VERSION "sdv-demo-powertrain-v2.0"

NS_ :

BS_:

BU_: VCU BMS Gateway

// ─── GLOBAL — ECU → Gateway, strictly VSS-aligned ───────────────────
// Every signal maps 1:1 to a VSS leaf; the Powertrain Gateway bridges
// CAN → KUKSA (read-only, sensor direction). Signal names follow the VSS
// leaf name. Cross-domain consumers (AAOS VHAL, AGL cluster) read these
// from KUKSA only — never off this bus.
//
// EV framing (no combustion engine). Producers (demo):
//   VCU = vcu.lua (speed / electric-motor rpm / odometer / gear / drive mode)
//   BMS = bms.lua (traction battery / range)

BO_ 256 PWT_VehicleSpeed: 4 VCU
 SG_ Speed_kph : 0|16@1+ (0.1,0) [0|300] "km/h" Gateway

BO_ 272 PWT_MotorSpeed: 2 VCU
 SG_ Speed_rpm : 0|16@1+ (0.25,0) [0|16000] "rpm" Gateway

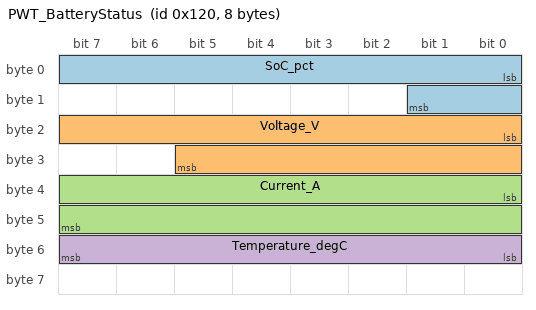
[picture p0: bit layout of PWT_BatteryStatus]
BO_ 288 PWT_BatteryStatus: 8 BMS
 SG_ SoC_pct : 0|10@1+ (0.1,0) [0|100] "%" Gateway
 SG_ Voltage_V : 16|14@1+ (0.1,0) [0|1000] "V" Gateway
 SG_ Current_A : 32|16@1- (0.1,0) [-3276.8|3276.7] "A" Gateway
 SG_ Temperature_degC : 48|8@1- (1,-40) [-40|150] "degC" Gateway

BO_ 304 PWT_Odometer: 4 VCU
 SG_ TraveledDistance_m : 0|32@1+ (1,0) [0|4294967295] "m" Gateway

BO_ 320 PWT_Range: 4 BMS
 SG_ Range_m : 0|32@1+ (1,0) [0|4294967295] "m" Gateway

BO_ 336 PWT_DrivetrainStatus: 2 VCU
 SG_ SelectedGear : 0|8@1- (1,0) [-128|127] "" Gateway
 SG_ PerformanceMode : 8|3@1+ (1,0) [0|4] "" Gateway

// SelectedGear uses the VSS-native int8 PRNDL encoding so the gateway is an
// identity passthrough to Vehicle.Powertrain.Transmission.SelectedGear.
VAL_ 336 SelectedGear -1 "REVERSE" 0 "NEUTRAL" 126 "PARK" 127 "DRIVE" ;
VAL_ 336 PerformanceMode 0 "NORMAL" 1 "SPORT" 2 "ECONOMY" 3 "SNOW" 4 "RAIN" ;

// ─── Cycle times (0 = event, non-zero = ms). Status frames cyclic so a
// late-joining Powertrain Gateway catches current state; matches the Lua
// publishers' cadence. nydus honours these on :publish. ───────────────
BA_DEF_ BO_ "GenMsgCycleTime" INT 0 10000;
BA_DEF_DEF_ "GenMsgCycleTime" 0;

BA_ "GenMsgCycleTime" BO_ 256 100;   // PWT_VehicleSpeed     — 10 Hz cluster speed
BA_ "GenMsgCycleTime" BO_ 272 50;    // PWT_MotorSpeed       — 20 Hz tachometer
BA_ "GenMsgCycleTime" BO_ 288 200;   // PWT_BatteryStatus    —  5 Hz BMS broadcast
BA_ "GenMsgCycleTime" BO_ 304 1000;  // PWT_Odometer         —  1 Hz odometer
BA_ "GenMsgCycleTime" BO_ 320 1000;  // PWT_Range            —  1 Hz range estimate
BA_ "GenMsgCycleTime" BO_ 336 100;   // PWT_DrivetrainStatus — 10 Hz gear / mode
